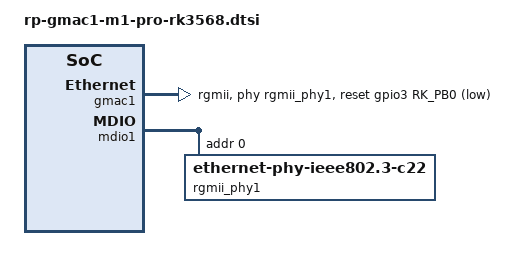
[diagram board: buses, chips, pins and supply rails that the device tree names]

&gmac1 {
	phy-mode = "rgmii";
	clock_in_out = "input";

//	snps,reset-gpio = <&gpio2 RK_PD1 GPIO_ACTIVE_LOW>;
	snps,reset-gpio = <&gpio3 RK_PB0 GPIO_ACTIVE_LOW>;
	snps,reset-active-low;
	/* Reset time is 20ms, 100ms for rtl8211f */
	snps,reset-delays-us = <0 20000 100000>;

	assigned-clocks = <&cru SCLK_GMAC1_RX_TX>, <&cru SCLK_GMAC1>, <&cru CLK_MAC1_OUT>;
	assigned-clock-parents = <&cru SCLK_GMAC1_RGMII_SPEED>,<&gmac1_clkin>, <&cru CLK_MAC1_2TOP>;
	assigned-clock-rates = <0>, <125000000>, <25000000>;

	pinctrl-names = "default";
	pinctrl-0 = <&gmac1m1_miim
		     &gmac1m1_tx_bus2
		     &gmac1m1_rx_bus2
		     &gmac1m1_rgmii_clk
		     &gmac1m1_rgmii_bus
	//		&eth1m0_pins
		&eth1m1_pins
			&gmac1m1_clkinout>;

	tx_delay = <0x3a>;
	rx_delay = <0x29>;
	phy-handle = <&rgmii_phy1>;
	status = "okay";
};


&mdio1 {
	rgmii_phy1: phy@0 {
		compatible = "ethernet-phy-ieee802.3-c22";
		reg = <0x0>;
		clocks = <&cru CLK_MAC1_OUT>;
	};
};

